VERSION "motion 0.3"

NS_ :

BS_:

BU_: HOST CTL

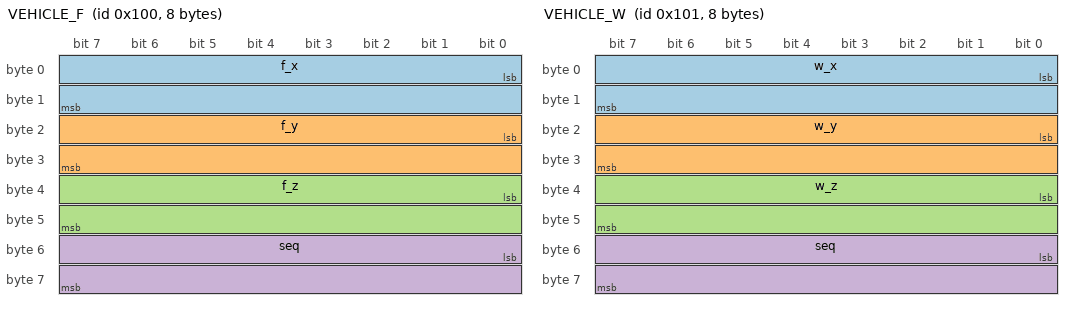
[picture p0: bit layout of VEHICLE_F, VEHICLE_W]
BO_ 256 VEHICLE_F: 8 HOST
 SG_ f_x : 0|16@1- (0.002,0) [-65.536|65.534] "m/s2" CTL
 SG_ f_y : 16|16@1- (0.002,0) [-65.536|65.534] "m/s2" CTL
 SG_ f_z : 32|16@1- (0.002,0) [-65.536|65.534] "m/s2" CTL
 SG_ seq : 48|16@1+ (1,0) [0|65535] "" CTL

BO_ 257 VEHICLE_W: 8 HOST
 SG_ w_x : 0|16@1- (0.0001,0) [-3.2768|3.2767] "rad/s" CTL
 SG_ w_y : 16|16@1- (0.0001,0) [-3.2768|3.2767] "rad/s" CTL
 SG_ w_z : 32|16@1- (0.0001,0) [-3.2768|3.2767] "rad/s" CTL
 SG_ seq : 48|16@1+ (1,0) [0|65535] "" CTL

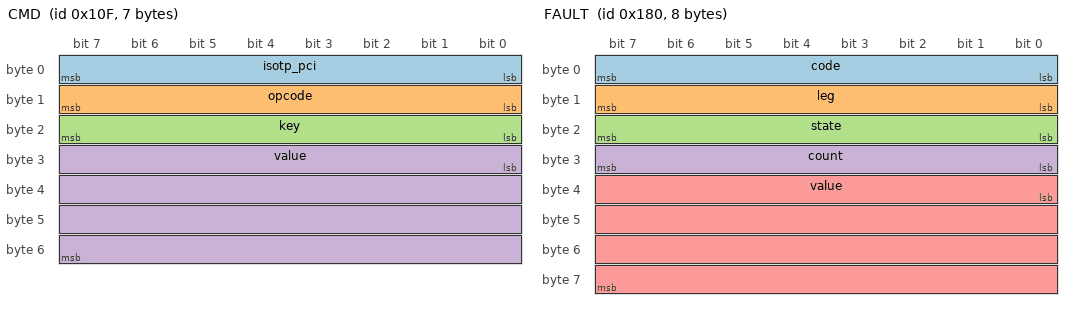
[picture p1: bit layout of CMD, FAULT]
BO_ 271 CMD: 7 HOST
 SG_ isotp_pci : 0|8@1+ (1,0) [6|6] "" CTL
 SG_ opcode : 8|8@1+ (1,0) [1|6] "" CTL
 SG_ key : 16|8@1+ (1,0) [0|255] "" CTL
 SG_ value : 24|32@1- (1,0) [-2147483648|2147483647] "" CTL

BO_ 384 FAULT: 8 CTL
 SG_ code : 0|8@1+ (1,0) [0|255] "" HOST
 SG_ leg : 8|8@1+ (1,0) [0|6] "" HOST
 SG_ state : 16|8@1+ (1,0) [0|7] "" HOST
 SG_ count : 24|8@1+ (1,0) [0|255] "" HOST
 SG_ value : 32|32@1- (1,0) [-2147483648|2147483647] "um or mA" HOST

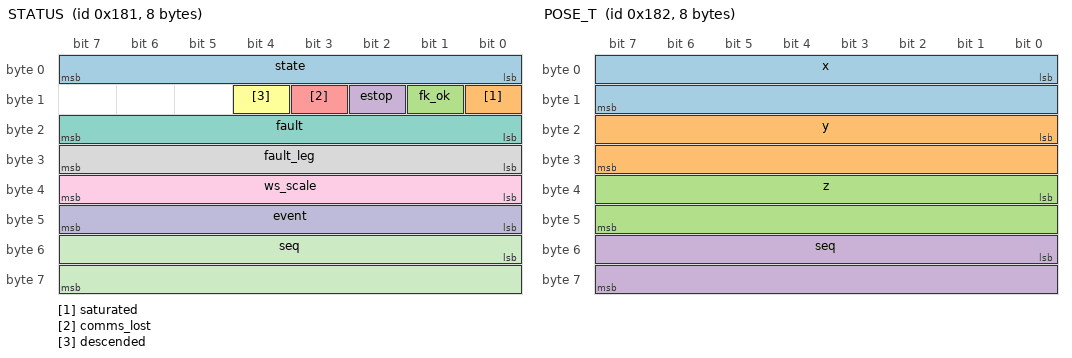
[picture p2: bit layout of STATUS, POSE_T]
BO_ 385 STATUS: 8 CTL
 SG_ state : 0|8@1+ (1,0) [0|7] "" HOST
 SG_ saturated : 8|1@1+ (1,0) [0|1] "" HOST
 SG_ fk_ok : 9|1@1+ (1,0) [0|1] "" HOST
 SG_ estop : 10|1@1+ (1,0) [0|1] "" HOST
 SG_ comms_lost : 11|1@1+ (1,0) [0|1] "" HOST
 SG_ descended : 12|1@1+ (1,0) [0|1] "" HOST
 SG_ fault : 16|8@1+ (1,0) [0|255] "" HOST
 SG_ fault_leg : 24|8@1+ (1,0) [0|6] "" HOST
 SG_ ws_scale : 32|8@1+ (0.005,0) [0|1.275] "" HOST
 SG_ event : 40|8@1+ (1,0) [0|255] "" HOST
 SG_ seq : 48|16@1+ (1,0) [0|65535] "" HOST

BO_ 386 POSE_T: 8 CTL
 SG_ x : 0|16@1- (0.0001,0) [-3.2768|3.2767] "m" HOST
 SG_ y : 16|16@1- (0.0001,0) [-3.2768|3.2767] "m" HOST
 SG_ z : 32|16@1- (0.0001,0) [-3.2768|3.2767] "m" HOST
 SG_ seq : 48|16@1+ (1,0) [0|65535] "" HOST

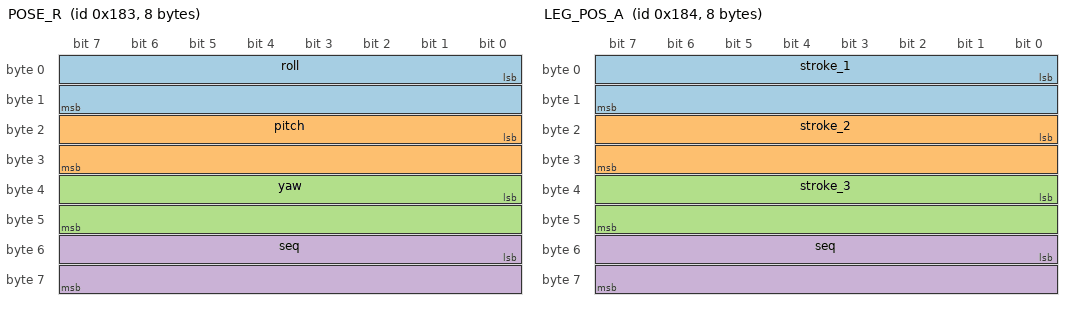
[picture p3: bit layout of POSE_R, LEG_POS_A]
BO_ 387 POSE_R: 8 CTL
 SG_ roll : 0|16@1- (0.01,0) [-327.68|327.67] "deg" HOST
 SG_ pitch : 16|16@1- (0.01,0) [-327.68|327.67] "deg" HOST
 SG_ yaw : 32|16@1- (0.01,0) [-327.68|327.67] "deg" HOST
 SG_ seq : 48|16@1+ (1,0) [0|65535] "" HOST

BO_ 388 LEG_POS_A: 8 CTL
 SG_ stroke_1 : 0|16@1+ (1e-05,0) [0|0.65535] "m" HOST
 SG_ stroke_2 : 16|16@1+ (1e-05,0) [0|0.65535] "m" HOST
 SG_ stroke_3 : 32|16@1+ (1e-05,0) [0|0.65535] "m" HOST
 SG_ seq : 48|16@1+ (1,0) [0|65535] "" HOST

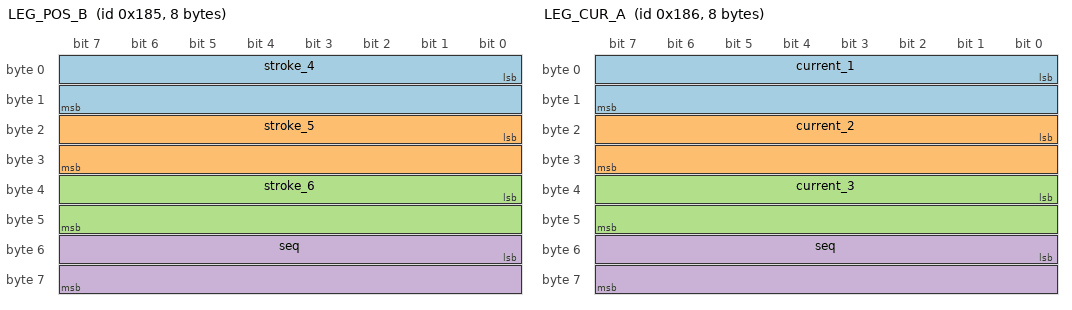
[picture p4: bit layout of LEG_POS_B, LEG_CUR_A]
BO_ 389 LEG_POS_B: 8 CTL
 SG_ stroke_4 : 0|16@1+ (1e-05,0) [0|0.65535] "m" HOST
 SG_ stroke_5 : 16|16@1+ (1e-05,0) [0|0.65535] "m" HOST
 SG_ stroke_6 : 32|16@1+ (1e-05,0) [0|0.65535] "m" HOST
 SG_ seq : 48|16@1+ (1,0) [0|65535] "" HOST

BO_ 390 LEG_CUR_A: 8 CTL
 SG_ current_1 : 0|16@1- (0.01,0) [-327.68|327.67] "A" HOST
 SG_ current_2 : 16|16@1- (0.01,0) [-327.68|327.67] "A" HOST
 SG_ current_3 : 32|16@1- (0.01,0) [-327.68|327.67] "A" HOST
 SG_ seq : 48|16@1+ (1,0) [0|65535] "" HOST

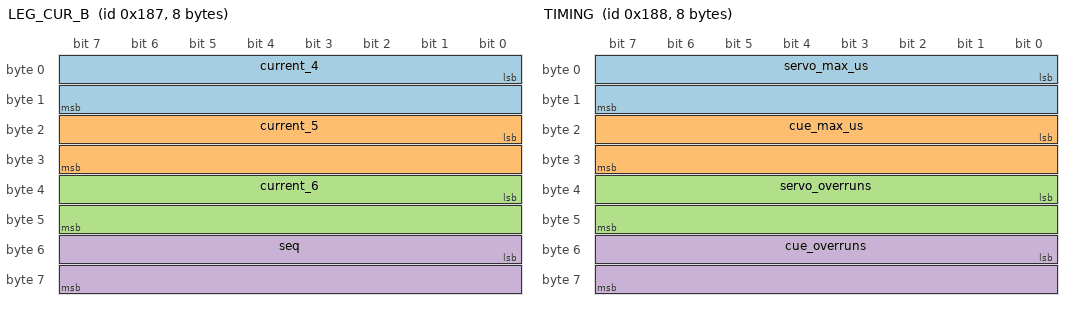
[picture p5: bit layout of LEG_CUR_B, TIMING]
BO_ 391 LEG_CUR_B: 8 CTL
 SG_ current_4 : 0|16@1- (0.01,0) [-327.68|327.67] "A" HOST
 SG_ current_5 : 16|16@1- (0.01,0) [-327.68|327.67] "A" HOST
 SG_ current_6 : 32|16@1- (0.01,0) [-327.68|327.67] "A" HOST
 SG_ seq : 48|16@1+ (1,0) [0|65535] "" HOST

BO_ 392 TIMING: 8 CTL
 SG_ servo_max_us : 0|16@1+ (1,0) [0|65535] "us" HOST
 SG_ cue_max_us : 16|16@1+ (1,0) [0|65535] "us" HOST
 SG_ servo_overruns : 32|16@1+ (1,0) [0|65535] "" HOST
 SG_ cue_overruns : 48|16@1+ (1,0) [0|65535] "" HOST

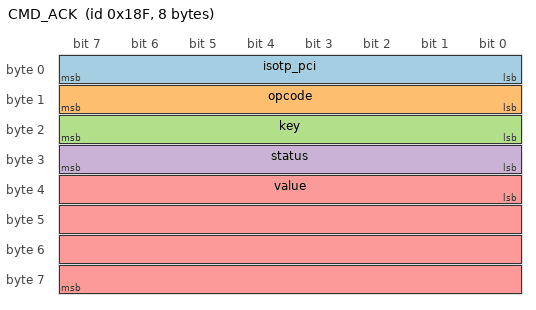
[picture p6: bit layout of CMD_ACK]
BO_ 399 CMD_ACK: 8 CTL
 SG_ isotp_pci : 0|8@1+ (1,0) [7|7] "" HOST
 SG_ opcode : 8|8@1+ (1,0) [1|6] "" HOST
 SG_ key : 16|8@1+ (1,0) [0|255] "" HOST
 SG_ status : 24|8@1+ (1,0) [0|255] "" HOST
 SG_ value : 32|32@1- (1,0) [-2147483648|2147483647] "" HOST

CM_ "6-DOF motion platform controller. Host IDs 0x100-0x10F, controller 0x180-0x18F. CMD / CMD_ACK are ISO-TP single frames (byte 0 = PCI).";
CM_ BO_ 256 "Vehicle specific force at the driver's head, 100 Hz. Paired with VEHICLE_W by seq.";
CM_ BO_ 257 "Vehicle angular rate (body frame), 100 Hz.";
CM_ BO_ 271 "Command. opcode 1 ENABLE, 2 ENGAGE, 3 PARK, 4 RESET_FAULT, 5 SET_PARAM, 6 GET_PARAM.";
CM_ BO_ 384 "Sent on every fault or event (code as mc_fault). leg 1..6, 0 = none.";
CM_ BO_ 385 "Platform status, 50 Hz.";
CM_ BO_ 388 "Leg stroke above the lower end stop, legs 1-3, 50 Hz.";
CM_ BO_ 392 "Loop timing, 1 Hz: worst cycle time since boot and overrun counts.";
CM_ BO_ 399 "Answer to CMD. status as mc_cmd_status.";
